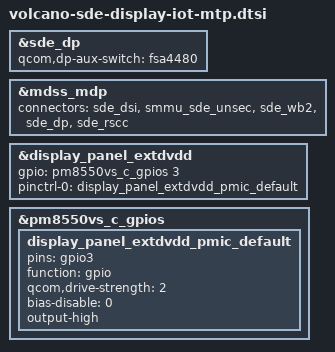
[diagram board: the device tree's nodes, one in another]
#include "volcano-sde-display-mtp.dtsi"

&sde_dp {
	status = "ok";
	qcom,dp-aux-switch = <&fsa4480>;
};

&mdss_mdp {
	connectors = <&sde_dsi &smmu_sde_unsec &sde_wb2 &sde_dp &sde_rscc>;
};

&display_panel_extdvdd {
	/delete-property/ gpio;
	/delete-property/ pinctrl-0;
	gpio = <&pm8550vs_c_gpios 3 0>;
	pinctrl-0 = <&display_panel_extdvdd_pmic_default>;
};

&pm8550vs_c_gpios {
	display_panel_extdvdd_pmic_default:
	display_panel_extdvdd_pmic_default {
		pins = "gpio3";
		function = "gpio";
		qcom,drive-strength = <2>;
		bias-disable = <0>;
		output-high;
	};
};
